# IWRL6432 register map
File version: 1.0
CPU: CM4 1.0, other endian, MPU, FPU, 3 interrupt priority bits
Registers are 32-bit, read-write, reset 0x0 unless marked. A register's access mark holds for its fields unless they carry their own. Offsets are from the block's base; [hi:lo] are bit positions; <NAME> marks a mode.

## APP_LIN (part 2 of 2)
Base 0x53000000
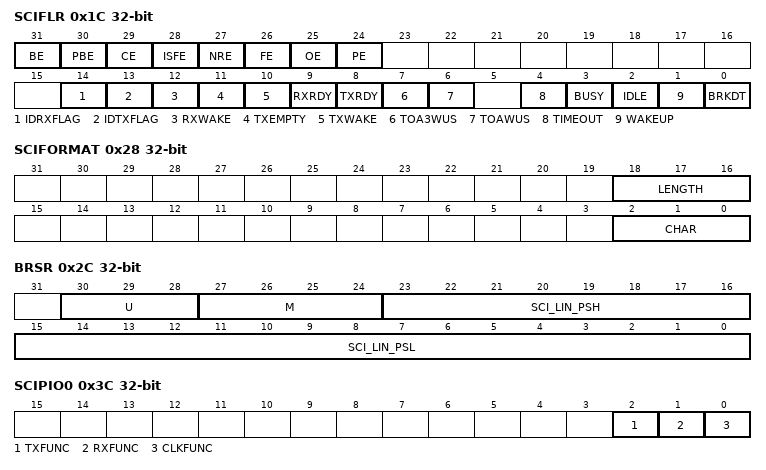
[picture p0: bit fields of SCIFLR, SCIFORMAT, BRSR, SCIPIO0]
0x1C SCIFLR — The SCIFLR register indicates the current status of the various interrupt sources of the LIN module.
  [31] BE — [31:31] Bit Error Flag. This bit is effective in LIN mode only. This bit is set when there has been a bit error. This is detected by the bit monitor in the internal bit monitor. This bit is cleared by: - Reading the corresponding interrupt offset in the SCIINTVECT0/1 register - Setting the SWnRESET bit (SCIGCR1.7) - RESET bit (SCIGCR0.0) - System reset - Writing a 1 to this bit - Reception of a new sync break This field is writable in LIN mode only.
  [30] PBE — [30:30] Physical Bus Error Flag. This bit is effective in LIN mode only. This bit is set when there has been a physical bus error. This is detected by the bit monitor in TED. This bit is cleared by: - Reading the corresponding interrupt offset in the SCIINTVECT0/1 register - Setting the SWnRESET bit (SCIGCR1.7) - RESET bit (SCIGCR0.0) - System reset - Writing a 1 to this bit - Reception of a new sync break Note: thie PBE will ony be flagged if no sync break can be generated. (because of a bus shortage to VBAT) or if no sync break delimeter can be generated (because of a bus shortage to GND). This field is writable in LIN mode only.
  [29] CE — [29:29] Checksum Error Flag. This bit is effective in LIN mode only. This bit is set when there is checksum error detected by a receiving node. The type of checksum to be used depends on the SCIGCR1.CTYPE bit. This bit is cleared by: - Reading the corresponding interrupt offset in the SCIINTVECT0/1 register - Setting the SWnRESET bit (SCIGCR1.7) - RESET bit (SCIGCR0.0) - System reset - Writing a 1 to this bit - Reception of a new sync break This field is writable in LIN mode only.
  [28] ISFE — [28:28] Inconsistent Sync Field Error Flag. This bit is effective in LIN mode only. This bit is set when there has been an inconsistent Sync Field error detected by the synchronizer during header reception. See the "Header Reception and Adaptive Baudrate" section for more information. This bit is cleared by: - Reading the corresponding interrupt offset in the SCIINTVECT0/1 register - Setting the SWnRESET bit (SCIGCR1.7) - RESET bit (SCIGCR0.0) - System reset - Writing a 1 to this bit - Reception of a new sync break This field is writable in LIN mode only.
  [27] NRE — [27:27] No-Response Error Flag. This bit is effective in LIN mode only. This bit is set when there is no response to a masterΓÇÖs header completed within TFRAME_MAX. This timeout period is applied for message frames of unknown length (identifiers 0 to 61). This error is detected by the synchronizer of the module. This bit is cleared by: - Reading the corresponding interrupt offset in the SCIINTVECT0/1 register - Setting the SWnRESET bit (SCIGCR1.7) - RESET bit (SCIGCR0.0) - System reset - Writing a 1 to this bit - Reception of a new sync break This field is writable in LIN mode only.
  [26] FE — [26:26] Framing error flag. This bit is effective in LIN or SCI-compatible mode. This bit is set when an expected stop bit is not found. In SCI compatible mode, only the first stop bit is checked. The missing stop bit indicates that synchronization with the start bit has been lost and that the character is incorrectly framed. Detection of a framing error causes the SCI to generate an error interrupt if the RXERR INT ENA bit is set. This bit is cleared by: - Reading the corresponding interrupt offset in the SCIINTVECT0/1 register - Setting the SWnRESET bit (SCIGCR1.7) - RESET bit (SCIGCR0.0) - System reset - Writing a 1 to this bit - Reception of a new character (SCI-compatible mode), or frame (LIN mode) In multibuffer mode the frame is defined in the SCIFORMAT register.
  [25] OE — [25:25] Overrun error flag. This bit is effective in LIN or SCI-compatible mode. This bit is set when the transfer of data from SCIRXSHF to SCIRD overwrites unread data already in SCIRD or the RDy buffers. Detection of an overrun error causes the LIN to generate an error interrupt if the SET OE INT bit is one. This bit is cleared by: - Reading the corresponding interrupt offset in the SCIINTVECT0/1 register - Setting the SWnRESET bit (SCIGCR1.7) - RESET bit (SCIGCR0.0) - System reset - Writing a 1 to this bit
  [24] PE — [24:24] Parity error flag. This bit is effective in LIN or SCI-compatible mode. This bit is set when a parity error is detected in the received data. In SCI address-bit mode, the parity is calculated on the data and address bit fields of the received frame. In idle-line mode, only the data is used to calculate parity. An error is generated when a character is received with a mismatch between the number of 1s and its parity bit. For more information on parity checking, see the "SCI Global Control Register (SCIGCR1)" description. If the parity function is disabled (that is, SCIGCR1.2 = 0), the PE flag is disabled and read as 0. Detection of a parity error causes the LIN to generate an error interrupt if the SET PE INT bit = 1. This bit is cleared by: - Reading the corresponding interrupt offset in the SCIINTVECT0/1 register - Setting the SWnRESET bit (SCIGCR1.7) - RESET bit (SCIGCR0.0) - System reset - Reception of a new charcter (SCI-compatible mode) or frame (LIN mode) - Writing a 1 to this bit
  [14] IDRXFLAG — [14:14] Identifier On Receive Flag. This bit is effective in LIN mode only. This flag is set once an identifier is received with an RX match and no ID-parity error. See the "Message Filtering and Validation" section for more details. When this flag is set it indicates that a new valid identifier has been received on an RX match. This bit is cleared by: - Reading the corresponding interrupt offset in the SCIINTVECT0/1 register - Setting the SWnRESET bit (SCIGCR1.7) - RESET bit (SCIGCR0.0) - System reset - Reading the LINID register - Writing a 1 to this bit This field is writable in LIN mode only.
  [13] IDTXFLAG — [13:13] Identifier On Transmit Flag. This bit is effective in LIN mode only. This flag is set once an identifier is received with a TX match and no ID-parity error. See the "Message Filtering and Validation" section for more details. When this flag is set it indicates that a new valid identifier has been received on a TX match. This bit is cleared by: - Reading the corresponding interrupt offset in the SCIINTVECT0/1 register - RESET bit (SCIGCR0.0) - Setting SWnRESET - System reset - Reading the LINID register - Writing a 1 to this bit This field is writable in LIN mode only.
  [12] RXWAKE — [12:12] Receiver wakeup detect flag. This bit is effective in SCI-compatible mode only. The SCI sets this bit to indicate that the data currently in SCIRD is an address. This bit is cleared by: - RESET bit - Setting the SWnRESET bit (SCIGCR1.7) - System reset - Receipt of a data frame This bit is writable in SCI mode only.
  [11] TXEMPTY — [11:11] Transmitter Empty flag. The value of this flag indicates the contents of the transmitterΓÇÖs buffer register(s) (SCITD/TDy) and shift register (SCITXSHF). In multibuffer mode, this flag indicates the value of the TDx registers and shift register (SCITXSHF). In non multibuffer mode, this flag indicates the value of LINTD0 (byte) and shift register (SCITXSHF). This bit is set by: - RESET bit (SCIGCR0.0) - Setting the SWnRESET bit (SCIGCR1.7) - System reset. Note: This bit does not cause an interrupt request.
  [10] TXWAKE — [10:10] SCI transmitter wakeup method select. This bit is effective in SCI-compatible mode only. The TXWAKE bit controls whether the data in SCITD should be sent as an address or data frame using multiprocessor communication format. This bit is set to 1 or 0 by software before a byte is written to SCITD and is cleared by the SCI when data is transferred from SCITD to SCITXSHF or by a system reset. TXWAKE is not cleared by the SWnRESET bit (SCIGCR1.7).
  [9] RXRDY — [9:9] Receiver ready flag. In SCI compatibility mode, the receiver sets this bit to indicate that the SCIRD contains new data and is ready to be read by the CPU. In LIN mode, RXRDY is set once a valid frame is received in multibuffer mode, a valid frame being a message frame received with no errors. In non multibuffer mode RXRDY is set for each received byte and will be set for the last byte of the frame if there are no errors. The SCI/LIN generates a receive interrupt when RXRDY flag bit is set if the interrupt-enable bit is set (SCISETINT.9). RXRDY is cleared by: - RESET bit (SCIGCR0.0) - Setting the SWnRESET - System reset - Writing a 1 to this bit - Reading SCIRD in while in SCI compatibility mode - Reading last data byte RDy of the response in LIN mode Note: The RXRDY flag cannot be cleared by reading the corresponding interrupt offset in the SCIINTVECT0/1 register.
  [8] TXRDY — [8:8] Transmitter buffer register ready flag. When set, this bit indicates that the transmit buffer(s) register (SCITD in compatibility mode and LINTD0, LINTD1 in MBUF mode) is/are ready to get another character from a CPU write. In SCI compatibility mode, writing data to SCITD automatically clears this bit. In LIN mode, this bit is cleared once byte 0 (TD0) is written to LINTD0. This bit is set after the data of the TX buffer are shifted into the SCITXSHF register. This event can trigger a transmit DMA event if the DMA enable bit is set. This bit is set to 1 by: - RESET bit (SCIGCR0.0) - Setting the SWnRESET (SCIGCR1.7) - System reset Note: The TXRDY flag cannot be cleared by reading the corresponding interrupt offset in the SCIINTVECT0/1 register. Note: The transmit interrupt request can be eliminated until the next series of data is written into the transmit buffers LINTD0 and LINTD1, by disaLINg the corresponding interrupt via the SCICLEARINT register or by disaLINg the transmitter via the TXENA bit (SCIGCR1.25=0).
  [7] TOA3WUS — [7:7] Timeout After 3 Wakeup Signals flag. This bit is effective in LIN mode only. This flag is set if there is no Sync Break received after 3 wakeup signals and a period of 1.5 seconds have passed. Such expiration time is used before issuing another round of wakeup signals. This bit is cleared by: - Reading the corresponding interrupt offset in the SCIINTVECT0/1 register - Setting the SWnRESET bit (SCIGCR1.7) - RESET bit (SCIGCR0.0) - System reset - Writing a 1 to this bit This field is writable in LIN mode only.
  [6] TOAWUS — [6:6] Timeout After Wakeup Signal flag. This bit is effective in LIN mode only. This bit is set if there is no Sync Break received after a wakeup signal has been sent. A minimum of 150 ms expiration time is used before issuing another wakeup signal. This bit is cleared by: - Reading the corresponding interrupt offset in the SCIINTVECT0/1 register - Setting the SWnRESET bit (SCIGCR1.7) - RESET bit (SCIGCR0.0) - System reset - Writing a 1 to this bit This field is writable in LIN mode only.
  [4] TIMEOUT — [4:4] LIN Bus IDLE timeout flag. This bit is effective in LIN mode only. This bit is set if there is no LIN bus activity for at least 4 seconds. LIN bus activity being a transition from recessive to dominant. This bit is cleared by: - Reading the corresponding interrupt offset in the SCIINTVECT0/1 register - Setting the SWnRESET bit (SCIGCR1.7) - RESET bit (SCIGCR0.0) - System reset - Writing a 1 to this bit This field is writable in LIN mode only.
  [3] BUSY — [3:3] Bus BUSY flag. This bit is effective in LIN mode and SCI-compatible mode. This bit indicates whether the receiver is in the process of receiving a frame. As soon as the receiver detects the beginning of a start bit, the BUSY bit is set to 1. When the reception of a frame is complete, the BUSY bit is cleared. If SET WAKEUP INT is set and power down is requested while this bit is set, the SCI/LIN automatically prevents low-power mode from being entered and generates wakeup interrupt. The BUSY bit is controlled directly by the SCI receiver but can be cleared by: - Setting the SWnRESET bit (SCIGCR1.7) - RESET bit (SCIGCR0.0) - System reset.
  [2] IDLE — [2:2] SCI receiver in idle state. This bit is effective in SCI-compatible mode only. While this bit is set, the SCI looks for an idle period to resynchronize itself with the bit stream. The receiver does not receive any data while the bit is set. The bus must be idle for 11 bit periods to clear this bit. The SCI enters this state: - After a system reset - Setting the SWnRESET bit (SCIGCR1.7) - After coming out of power down This bit is writable in SCI mode only.
  [1] WAKEUP — [1:1] Wake-up flag. This bit is effective in LIN mode only. This bit is set by the SCI/LIN when receiver or transmitter activity has taken the module out of power-down mode. An interrupt is generated if the SET WAKEUP INT bit (SCISETINT.1) is set. This bit is cleared by: - Reading the corresponding interrupt offset in the SCIINTVECT0/1 register. - Setting the SWnRESET bit (SCIGCR1.7) - RESET bit (SCIGCR0.0) - System reset - Writing a 1 to this bit. This field is writable in LIN mode only.
  [0] BRKDT — [0:0] SCI break-detect flag. This bit is effective in SCI-compatible mode only. This bit is set when the SCI detects a break condition on the LINRX pin. A break condition occurs when the LINRX pin remains continuously low for at least 10 bits after a missing first stop bit, that is, after a framing error. Detection of a break condition causes the SCI to generate an error interrupt if the BRKDT INT ENA bit is set. The BRKDT bit is cleared by the following: - Reading the corresponding interrupt offset in the SCIINTVECT0/1 register. - Setting the SWnRESET bit (SCIGCR1.7) - RESET bit (SCIGCR0.0) - System reset - By writing a 1 to this bit. This bit is writable in SCI mode only.
0x20 SCIINTVECT0 — The SCIINTVECT0 register indicates the offset for the INT0 interrupt line.
  [4:0] INTVECT0 — [4:0] Interrupt vector offset for INT0. This register indicates the offset for interrupt line INT0. A read to this register updates its value to the next highest priority pending interrupt in SCIFLR and clears the flag corresponding to the offset that was read. Note: The flags for the receive (SCIFLR.9) and the transmit (SCIFLR.8) interrupts cannot be cleared by reading the corresponding offset vector in this register (see detailed description in SCIFLR register).
0x24 SCIINTVECT1 — The SCIINTVECT1 register indicates the offset for the INT1 interrupt line.
  [4:0] INTVECT1 — [4:0] Interrupt vector offset for INT1. This register indicates the offset for interrupt line INT1. A read to this register updates its value to the next highest priority pending interrupt in SCIFLR and clears the flag corresponding to the offset that was read. Note: The flags for the receive (SCIFLR.9) and the transmit (SCIFLR.8) interrupts cannot be cleared by reading the corresponding offset vector in this register (see detailed description in SCIFLR register).
0x28 SCIFORMAT — The SCIFORMAT register is used to set up the character and frame lengths.
  [18:16] LENGTH — [18:16] Frame length control bits. In LIN mode, these bits indicate the number of bytes in the response field from 1 to 8 bytes. In buffered SCI mode, these bits indicate the number of characters. When these bits are used to indicate LIN response length (SCIGCR1[0] = 1), then when there is an ID RX match, this value should be updated with the expected length of the response. In buffered SCI mode, these bits indicate the number of characters with SCIFORMAT[2:0] bits per character. i.e. these bits indicate the transmitter/receiver format for the number of characters: 1 to 8. There can be up to eight characters with eight bits each.
  [2:0] CHAR — [2:0] Character length control bits. These bits are effective in SCI compatible mode only. These bits set the SCI character length from 1 to 8 bits. Note: In compatibility mode or buffered SCI mode, when data of fewer than eight bits in length is received, it is left justified in SCIRD/RDy and padded with trailing zeros. Data read from the SCIRD should be shifted by software to make the received data right justified. Note: Data written to the SCITD should be right justified but does not need to be padded with leading zeros. These bits are witable in SCI mode only.
0x2C BRSR — The BRSR register is used to configure the baud rate of the LIN module.
  [30:28] U — [30:28] Superfractional Divider Selection. (U) These bits are an additional fractional part for the baudrate specification. These bits allow a super fine tuning of the fractional baudrate with 7 more intermediate values for each of the M fractional divider values. See the Superfractional Divider section for more details.
  [27:24] M — [27:24] SCI/LIN 4-bit Fractional Divider Selection. (M) These bits are effective in LIN or SCI asynchronous mode. These bits are used to select a baud rate for the SCI/LIN module, and they are a fractional part for the baud rate specification. The M divider allows fine-tuning of the baud rate over the P prescaler with 15 additional intermediate values for each of the P integer values.
  [23:16] SCI_LIN_PSH — [23:16] PRESCALER P (High Bits). SCI/LIN 24-bit Integer Prescaler Selection. These bits are used to select a baudrate for the SCI/LIN module. These bits are effective in LIN mode and SCI compatible mode. The SCI/LIN has an internally generated serial clock determined by the LIN module input clock and the prescalers P and M in this register. The SCI/LIN uses the 24-bit integer prescaler P value to select 1 of over 16,700,000 available baud rates. The additional 4-bit fractional prescaler M refines the baudate selection.
  [15:0] SCI_LIN_PSL — [15:0] PRESCALER P (Low Bits). SCI/LIN 24-bit Integer Prescaler Selection. These bits are used to select a baudrate for the SCI/LIN module. These bits are effective in LIN mode and SCI compatible mode. The SCI/LIN has an internally generated serial clock determined by the LIN module input clock and the prescalers P and M in this register. The SCI/LIN uses the 24-bit integer prescaler P value to select 1 of over 16,700,000 available baud rates. The additional 4-bit fractional prescaler M refines the baudate selection.
0x30 SCIED — The SCIED register is a duplicate copy of SCIRD register that has no affect on the RXRDY flag for use with an emulator.
  [7:0] ED — [7:0] Receiver Emulation Data. This bit is effective in SCI-compatible mode only. Reading SCIED(7ΓÇô0) does not clear the RXRDY flag. This register should be used only by an emulator that must continually read the data buffer without affecting the RXRDY flag.
0x34 SCIRD — The SCIRD register is where received data is stored and can be read from.
  [7:0] RD — [7:0] Received Data. This bit is effective in SCI-compatible mode only. When a frame has been completely received, the data in the frame is transferred from the receiver shift register SCIRXSHF to this register. As this transfer occurs, the RXRDY flag is set and a receive interrupt is generated if RX INT ENA (SCISETINT0.9) is set. When the data is read from SCIRD, the RXRDY flag is automatically cleared. When the SCI receives data that is fewer than eight bits in length, it loads the data into this register in a left justified format padded with trailing zeros. Therefore, your software should perform a logical shift on the data by the correct number of positions to make it right justified.
0x38 SCITD — The SCITD register is where data to be transmitted is written to by application software.
  [7:0] TD — [7:0] Transmit data This bit is effective in SCI-compatible mode only. Data to be transmitted is written to this register. The transfer of data from this register to the transmit shift register SCITXSHF sets the TXRDY flag (SCIFLR.23), which indicates that SCITD is ready to be loaded with another byte of data. Note: If TX INT ENA (SCISETINT.8) is set, this data transfer also causes an interrupt. Note: Data written to the SCIRD register that is fewer than eight bits long must be right justified, but it does not need to be padded with leading zeros.
0x3C SCIPIO0 — The SCIPIO0 register is used to enable the LINTX and LINRX pins.
  [2] TXFUNC — [2:2] Transmit pin function. This bit is effective in LIN or SCI mode. This bit defines the function of LINTX pin.
  [1] RXFUNC — [1:1] Receive pin function. This bit is effective in LIN or SCI mode. This bit defines the function of the LINRX pin.
  [0] CLKFUNC — [0:0] Reserved
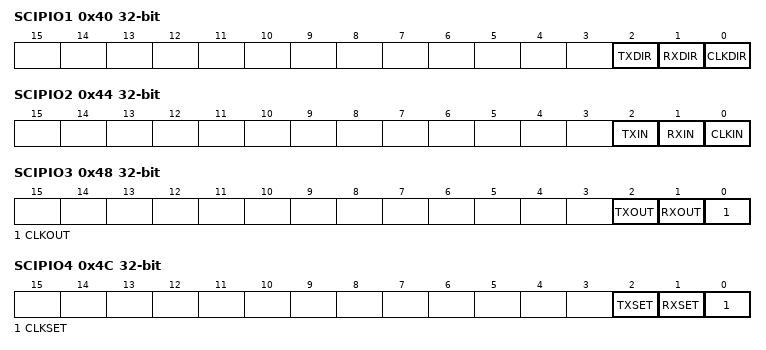
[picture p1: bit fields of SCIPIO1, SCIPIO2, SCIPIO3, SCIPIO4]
0x40 SCIPIO1
  [2] TXDIR — [2:2] Transmit pin direction. This bit is effective in LIN or SCI mode. This bit determines the data direction on the LINTX pin if it is configured with general-purpose I/O functionality (TX FUNC = 0). 0: general purpose input pin. 1: general-purpose output pin
  [1] RXDIR — [1:1] Receive pin direction. This bit is effective in LIN or SCI mode. This bit determines the data direction on the LINRX pin if it is configured with general-purpose I/O functionality (RX FUNC = 0). 0: general purpose input pin. 1: general-purpose output pin
  [0] CLKDIR — [0:0] Reserved
0x44 SCIPIO2 — The SCIPIO2 register indicates the current status of the LINTX and LINRX pins.
  [2] TXIN — [2:2] Transmit data in. This bit is effective in LIN or SCI-compatible mode. This bit contains the current value on the LINTX pin.
  [1] RXIN — [1:1] Receive data in. This bit is effective in LIN or SCI-compatible mode. This bit contains the current value on the LINRX pin.
  [0] CLKIN — [0:0] Reserved
0x48 SCIPIO3
  [2] TXOUT — [2:2] Transmit pin out. This bit is effective in LIN or SCI mode. This pin specifies the logic to be output on pin LINTX.
  [1] RXOUT — [1:1] Receive pin out. This bit is effective in LIN or SCI mode. This pin specifies the logic to be output on pin LINRX.
  [0] CLKOUT — [0:0] Reserved
0x4C SCIPIO4
  [2] TXSET — [2:2] Transmit pin set. This bit is effective in LIN or SCI mode. This bit sets the logic to be output on pin LINTX.
  [1] RXSET — [1:1] Receive pin set. This bit is effective in LIN or SCI mode. This bit sets the logic to be output on pin LINRX.
  [0] CLKSET — [0:0] Reserved
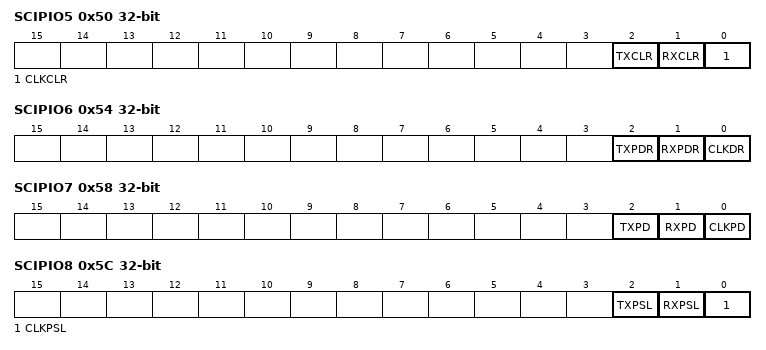
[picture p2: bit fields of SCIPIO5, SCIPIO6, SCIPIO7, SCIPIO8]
0x50 SCIPIO5
  [2] TXCLR — [2:2] Transmit pin clear. This bit is effective in LIN or SCI mode. This bit clears the logic to be output on pin LINTX.
  [1] RXCLR — [1:1] Receive pin clear. This bit is effective in LIN or SCI mode. This bit clears the logic to be output on pin LINRX.
  [0] CLKCLR — [0:0] Reserved
0x54 SCIPIO6
  [2] TXPDR — [2:2] Transmit pin open drain enable. This bit is effective in LIN or SCI mode. This bit enables open-drain capability in the output pin LINTX.
  [1] RXPDR — [1:1] Receive pin open drain enable. This bit is effective in LIN or SCI mode. This bit enables open-drain capability in the output pin LINRX.
  [0] CLKDR — [0:0] Reserved
0x58 SCIPIO7
  [2] TXPD — [2:2] Transmit pin pull control disable. This bit is effective in LIN or SCI mode. This bit disables pull control capability on the input pin LINTX.
  [1] RXPD — [1:1] Receive pin pull control disable. This bit is effective in LIN or SCI mode. This bit disables pull control capability on the input pin LINRX.
  [0] CLKPD — [0:0] Reserved
0x5C SCIPIO8
  [2] TXPSL — [2:2] TX pin pull select. This bit is effective in LIN or SCI mode. This bit selects pull type in the input pin LINTX.
  [1] RXPSL — [1:1] RX pin pull select. This bit is effective in LIN or SCI mode. This bit selects pull type in the input pin LINRX.
  [0] CLKPSL — [0:0] Reserved
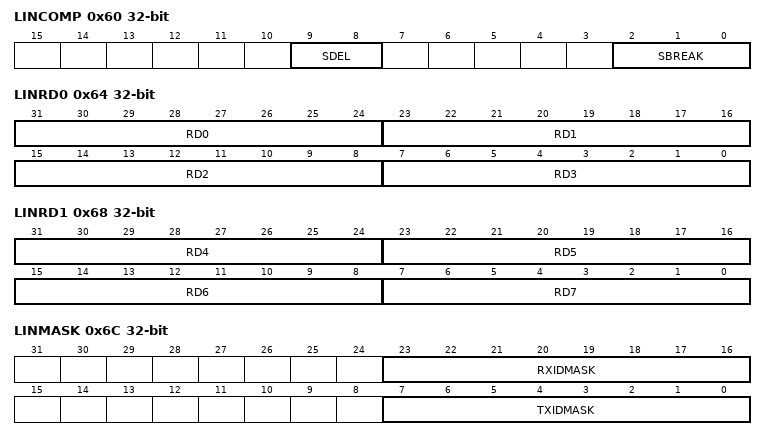
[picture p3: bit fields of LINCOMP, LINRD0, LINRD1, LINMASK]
0x60 LINCOMP — The LINCOMPARE register is used to configure the sync delimeter and sync break extension.
  [9:8] SDEL — [9:8] 2-bit Sync Delimiter compare. These bits are effective in LIN mode only. These bits are used to configure the number of Tbit for the sync delimiter in the sync field. The time delay calculation for the synchronization delimiter is: TSDEL = (SDEL + 1)Tbit These bits are writable in LIN mode only.
  [2:0] SBREAK — [2:0] 3-bit Sync Break extend. LIN mode only. These bits are used to configure the number of Tbits for the sync break to extend the minimum 13 Tbit in the Sync Field to a maximum of 20 Tbit. The time delay calculation for the sync break is: TSYNBRK = 13Tbit + SBREAK x Tbit These bits are writable in LIN mode only.
0x64 LINRD0 — The LINRD0 register contains the lower 4 bytes of the received LIN frame data.
  [31:24] RD0 — [31:24] 8-bit Receive Buffer 0 Each response data-byte that is received in the SCIRXSHFT register is transferred to the corresponding RDy register according to the number of bytes received. A read of this byte clears the RXDY byte. Note: RD<x-1> is equivalent to Data byte <x> of the LIN frame.
  [23:16] RD1 — [23:16] 8-bit Receive Buffer 1. Each response data-byte that is received in the SCIRXSHFT register is transferred to the corresponding RDy register according to the number of bytes received.
  [15:8] RD2 — [15:8] 8-bit Receive Buffer 2. Each response data-byte that is received in the SCIRXSHFT register is transferred to the corresponding RDy register according to the number of bytes received.
  [7:0] RD3 — [7:0] 8-bit Receive Buffer 3. Each response data-byte that is received in the SCIRXSHFT register is transferred to the corresponding RDy register according to the number of bytes received.
0x68 LINRD1 — The LINRD1 regsiter contains the upper 4 bytes of the received LIN frame data.
  [31:24] RD4 — [31:24] 8-bit Receive Buffer 4 Each response data-byte that is received in the SCIRXSHFT register is transferred to the corresponding RDy register according to the number of bytes received.
  [23:16] RD5 — [23:16] 8-bit Receive Buffer 5. Each response data-byte that is received in the SCIRXSHFT register is transferred to the corresponding RDy register according to the number of bytes received.
  [15:8] RD6 — [15:8] 8-bit Receive Buffer 6. Each response data-byte that is received in the SCIRXSHFT register is transferred to the corresponding RDy register according to the number of bytes received.
  [7:0] RD7 — [7:0] 8-bit Receive Buffer 7. Each response data-byte that is received in the SCIRXSHFT register is transferred to the corresponding RDy register according to the number of bytes received.
0x6C LINMASK — The LINMASK register is used to configure the masks used for filtering incoming ID messages for receive and transmit frames.
  [23:16] RXIDMASK — [23:16] Receive ID mask. This field is effective in LIN mode only.This 8-bit mask is used for filtering an incoming ID message and compare it to the ID-byte. A compare match of the received ID witht the RX ID mask will set the ID RX flag and trigger and ID interrupt if enabled. A 0 bit in the mask indicates that bit is compared to the ID-byte. A 1 bit in the mask indicates that that bit is filtered and therefore not used in the compare. When HGENCTRL is set to 1, this field must be set to 0xFF.
  [7:0] TXIDMASK — [7:0] Transmit ID mask. This field is effective in LIN mode only. This 8-bit mask is used for filtering an incoming ID message and compare it to the ID-byte. A compare match of the received ID with the TX ID Mask will set the ID TX flag and trigger an ID interrupt if enabled. A 0 bit in the mask indicates that bit is compared to the ID-byte. A 1 bit in the mask indicates that bit is filtered and therefore not used for the compare. When HGENCTRL is set to 1, this field must be set to 0xFF.
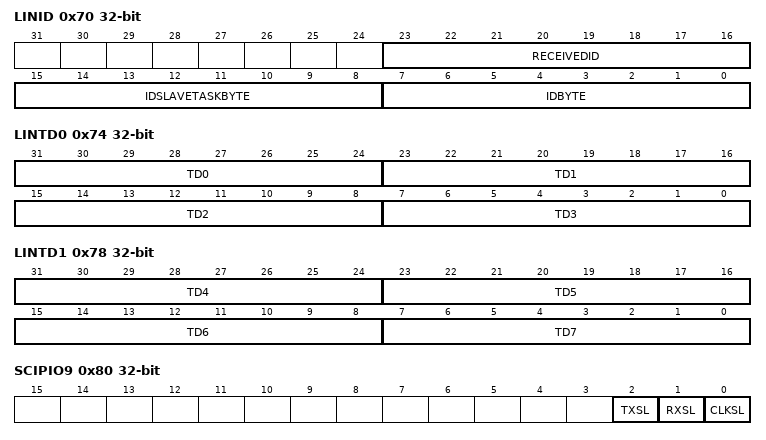
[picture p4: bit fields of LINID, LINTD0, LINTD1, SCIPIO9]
0x70 LINID — The LINID register contains the identification fields for LIN communication. NOTE: For software compatibility with future LIN modules, the HGEN CTRL bit must be set to 1, the RX ID MASK field must be set to FFh, and the TX ID MASK field must be set to FFh.
  [23:16] RECEIVEDID — [23:16] Received ID. This bit is effective in LIN mode only. This byte contains the current message identifier. During header reception the received ID is copied from the SCIRXSHF register to this byte if there is no ID-parity error and there has been an RX/TX match. Note: If a framing error (FE) is detected during ID reception, the received ID will also not be copied to the LINID register.
  [15:8] IDSLAVETASKBYTE — [15:8] ID Slave Task byte. This field is effective in LIN mode only. This byte contains the identifier to which the received ID of an incoming header will be compared in order to decide whether a RX response, a TX response, or no action needs to be done by the LIN node. These bits are writable in LIN mode only.
  [7:0] IDBYTE — [7:0] ID byte. This field is effective in LIN mode only. This byte is the LIN mode message ID. On a master node, a write to this register by the CPU initiates a header transmission. For a slave task, this byte is used for message filtering when HGENCTRL (SCIGCR1.12) is '0'. These bits are writable in LIN mode only.
0x74 LINTD0 — The LINTD0 register contains the lower 4 bytes of the data to be transmitted. NOTE: TD<x-1> is equivalent to Data byte <x> of the LIN frame.
  [31:24] TD0 — [31:24] 8-bit Transmit Buffer 0. Byte 0 to be transmitted is written into this register and then copied to SCITXSHF for transmission. Once byte 0 is written in TDO buffer, transmission will be initiated.
  [23:16] TD1 — [23:16] 8-bit Transmit Buffer 3. Byte 1 to be transmitted is written into this register and then copied to SCITXSHF for transmission.
  [15:8] TD2 — [15:8] 8-bit Transmit Buffer 2. Byte 2 to be transmitted is written into this register and then copied to SCITXSHF for transmission.
  [7:0] TD3 — [7:0] 8-bit Transmit Buffer 3. Byte 3 to be transmitted is written into this register and then copied to SCITXSHF for transmission.
0x78 LINTD1 — The LINTD1 register contains the upper 4 bytes of the data to be transmitted. NOTE: TD<x-1> is equivalent to Data byte <x> of the LIN frame.
  [31:24] TD4 — [31:24] 8-bit Transmit Buffer 4. Byte4 to be transmitted is written into this register and then copied to SCITXSHF for transmission.
  [23:16] TD5 — [23:16] 8-bit Transmit Buffer 5. Byte 5 to be transmitted is written into this register and then copied to SCITXSHF for transmission.
  [15:8] TD6 — [15:8] 8-bit Transmit Buffer 6. Byte 6 to be transmitted is written into this register and then copied to SCITXSHF for transmission.
  [7:0] TD7 — [7:0] 8-bit Transmit Buffer 7. Byte 7 to be transmitted is written into this register and then copied to SCITXSHF for transmission.
0x7C MBRSR — The MBRSR register is used to configure the expected maximum baud rate of the LIN network.
  [12:0] MBR — [12:0] Maximum Baud Rate Prescaler. This field is effective in LIN mode only. This 13-bit prescaler is used during the synchronization phase (see the "Header Reception and Adaptive Baudrate" section) of a slave module if the ADAPT bit is set. In this way, a SCI/LIN slave using an automatic or select bit rate modes detects any LIN bus legal rate automatically. The MBR value should be programmed to allow a maximum baud rate that is not more than 10% above the expected operating baud rate in the LIN network. Otherwise a s 0x00 data byte could mistakenly be detected as sync break. The default value is for a 70MHz LINCLK (0xDAC). This MBR prescaler is used by the wake-up and idle time counters for a constant expiration time relative to a 20kHz rate.
0x80 SCIPIO9 — Couldn't find this register in spec. But it's mentioned in RTL.
  [2] TXSL — [2:2] SCITX PIN value
  [1] RXSL — [1:1] SCIRX PIN value
  [0] CLKSL — [0:0] Reserved
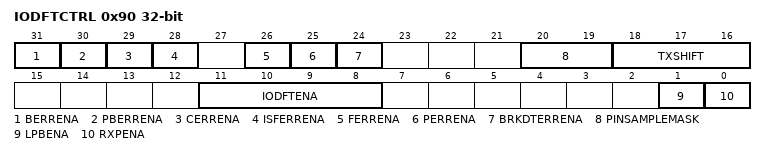
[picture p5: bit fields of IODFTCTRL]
0x90 IODFTCTRL — The IODFTCTRL register is used to emulate various error and test conditions.
  [31] BERRENA — [31:31] Bit Errror Enable bit. This bit is effective in LIN mode only. This bit is used to create a Bit error. When this bit is set, the bit received is ORed with 1 and passed to the Bit monitor circuitry.
  [30] PBERRENA — [30:30] Physical Bus Error Enable bit. This bit is effective in LIN mode only. This bit is used to create a Physical Bus Error. When this bit is set, the bit received during Sync Break field transmission is ORed with 1 and passed to the Bit monitor circuitry
  [29] CERRENA — [29:29] Checksum Error Enable bit. This bit is effective in LIN mode only. This bit is used to create a checksum error. When this bit is set, the polarity of the CTYPE (checksum type) in the receive checksum calculator is changed so that a checksum error is generated.
  [28] ISFERRENA — [28:28] Inconsistent Sync Field Error Enable bit. This bit is effective in LIN mode only. This bit is used to create an ISF error. When this bit is set, the bit widths in the sync field are varied so that the ISF check fails and the error flag is set.
  [26] FERRENA — [26:26] This bit is used to create a Frame Error. This bit is effective in SCI-compatible mode only. When this bit is set, the stop bit received is ANDed with ΓÇÖ0ΓÇÖ and passed to the stop bit check circuitry.
  [25] PERRENA — [25:25] Compatible Mode only This bit is effective in SCI-compatible mode only. This bit is used to create a Parity Error. When this bit is set, in compatible mode, the parity bit received is toggled so that a parity error occurs.
  [24] BRKDTERRENA — [24:24] Compatible Mode only This bit is effective in SCI-compatible mode only. This bit is used to create BRKDT error (SCI mode only). When this bit is set, the stop bit of the frame is ANDed with ΓÇÖ0ΓÇÖ and passed to the RSM so that a frame error occurs. Then the RX Pin is forced to continuous low for 10 Tbits so that a BRKDT error occurs.
  [20:19] PINSAMPLEMASK — [20:19] Pin sample mask. These bits define the sample number at which the TX Pin value that is being transmitted will be inverted to verify the receive pin samples correctly with the majority detection circuitry. Note: During IODFT mode testing for the pin sample mask, the prescalar P must be programmed to be greater than 2.
  [18:16] TXSHIFT — [18:16] Transmit shift. These bits define the delay by which the value on LINTX is delayed so that the value on LINRX is asynchronous. (Not applicable to Start Bit)
  [11:8] IODFTENA — [11:8] IO DFT Enable Key This field is used to enable the IODFT mode of the SCI/LIN module for testing. Writable Only in privilege mode
  [1] LPBENA — [1:1] Module loopback enable. In analog loopback mode the complete communication path through the I/Os can be tested, whereas in digital loopback mode the I/O buffers are excluded from this path. Writable Only in privilege mode
  [0] RXPENA — [0:0] Module Analog loopback through receive pin enable. This bit defines whether the I/O buffers for the transmit or the receive pin are included in the communication path in analog loopback mode only. Writable Only in privilege mode
